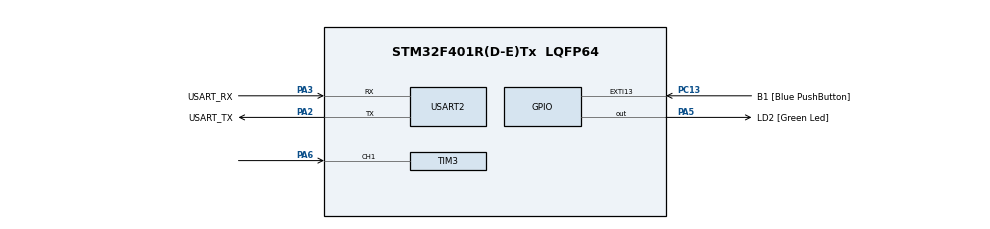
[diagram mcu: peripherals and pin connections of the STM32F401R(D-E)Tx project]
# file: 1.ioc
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Mcu.Family=STM32F4
Mcu.Name=STM32F401R(D-E)Tx
Mcu.Package=LQFP64
NVIC.PriorityGroup=NVIC_PRIORITYGROUP_0
NVIC.TIM3_IRQn=true\:0\:0\:false\:false\:true\:true\:true
PA13.GPIO_Label=TMS
PA13.Mode=Serial_Wire
PA13.Signal=SYS_JTMS-SWDIO
PA14.GPIO_Label=TCK
PA14.Mode=Serial_Wire
PA14.Signal=SYS_JTCK-SWCLK
PA2.GPIO_Label=USART_TX
PA2.GPIO_Mode=GPIO_MODE_AF_PP
PA2.GPIO_PuPd=GPIO_NOPULL
PA2.GPIO_Speed=GPIO_SPEED_FREQ_LOW
PA2.Mode=Asynchronous
PA2.Signal=USART2_TX
PA3.GPIO_Label=USART_RX
PA3.GPIO_Mode=GPIO_MODE_AF_PP
PA3.GPIO_PuPd=GPIO_NOPULL
PA3.GPIO_Speed=GPIO_SPEED_FREQ_LOW
PA3.Mode=Asynchronous
PA3.Signal=USART2_RX
PA5.GPIO_Label=LD2 [Green Led]
PA5.GPIO_Mode=GPIO_MODE_OUTPUT_PP
PA5.GPIO_PuPd=GPIO_NOPULL
PA5.GPIO_Speed=GPIO_SPEED_FREQ_LOW
PA5.Signal=GPIO_Output
PA6.Signal=S_TIM3_CH1
PB3.GPIO_Label=SWO
PB3.Signal=SYS_JTDO-SWO
PC13-ANTI_TAMP.GPIO_Label=B1 [Blue PushButton]
PC13-ANTI_TAMP.GPIO_ModeDefaultEXTI=GPIO_MODE_IT_FALLING
PC13-ANTI_TAMP.GPIO_PuPd=GPIO_NOPULL
PC13-ANTI_TAMP.Signal=GPXTI13
PC14-OSC32_IN.Mode=LSE-External-Oscillator
PC14-OSC32_IN.Signal=RCC_OSC32_IN
PC15-OSC32_OUT.Mode=LSE-External-Oscillator
PC15-OSC32_OUT.Signal=RCC_OSC32_OUT
PH0\ -\ OSC_IN.Mode=HSE-External-Clock-Source
PH0\ -\ OSC_IN.Signal=RCC_OSC_IN
PH1\ -\ OSC_OUT.Mode=HSE-External-Clock-Source
PH1\ -\ OSC_OUT.Signal=RCC_OSC_OUT
ProjectManager.HeapSize=0x200
ProjectManager.StackSize=0x400
ProjectManager.TargetToolchain=SW4STM32
RCC.48MHZClocksFreq_Value=48000000
RCC.AHBFreq_Value=84000000
RCC.APB1CLKDivider=RCC_HCLK_DIV2
RCC.APB1Freq_Value=42000000
RCC.APB1TimFreq_Value=84000000
RCC.APB2Freq_Value=84000000
RCC.APB2TimFreq_Value=84000000
RCC.CortexFreq_Value=84000000
RCC.HCLKFreq_Value=84000000
RCC.HSE_VALUE=8000000
RCC.HSI_VALUE=16000000
RCC.PLLN=336
RCC.PLLP=RCC_PLLP_DIV4
RCC.PLLQ=7
RCC.SYSCLKFreq_VALUE=84000000
RCC.SYSCLKSource=RCC_SYSCLKSOURCE_PLLCLK
RCC.VCOOutputFreq_Value=336000000
SH.S_TIM3_CH1.0=TIM3_CH1,Input_Capture1_from_TI1
TIM3.Channel-Input_Capture1_from_TI1=TIM_CHANNEL_1
TIM3.ICPolarity_CH1=TIM_INPUTCHANNELPOLARITY_BOTHEDGE
TIM3.Period=0xFFFF
TIM3.Prescaler=1999
USART2.VirtualMode=VM_ASYNC
VP_TIM3_VS_ClockSourceINT.Mode=Internal
board=NUCLEO-F401RE

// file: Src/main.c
/* USER CODE BEGIN Header */
/**
  ******************************************************************************
  * @file      10.1     : main.c
  * @brief          : Main program body
  ******************************************************************************
  * @attention
  *
  * <h2><center>&copy; Copyright (c) 2019 STMicroelectronics.
  * All rights reserved.</center></h2>
  *
  * This software component is licensed by ST under BSD 3-Clause license,
  * the "License"; You may not use this file except in compliance with the
  * License. You may obtain a copy of the License at:
  *                        opensource.org/licenses/BSD-3-Clause
  *
  ******************************************************************************
  */
/* USER CODE END Header */

#include "main.h"

void SystemClock_Config(void);
static void MX_GPIO_Init(void);
static void MX_TIM3_Init(void);
static void MX_USART2_UART_Init(void);

int main(void)
{

  /* MCU Configuration--------------------------------------------------------*/

  /* Reset of all peripherals, Initializes the Flash interface and the Systick. */

  LL_APB2_GRP1_EnableClock(LL_APB2_GRP1_PERIPH_SYSCFG);
  LL_APB1_GRP1_EnableClock(LL_APB1_GRP1_PERIPH_PWR);

  NVIC_SetPriorityGrouping(NVIC_PRIORITYGROUP_0);

  /* System interrupt init*/

  /* Configure the system clock */
  SystemClock_Config();

  /* Initialize all configured peripherals */
  MX_GPIO_Init();
  MX_TIM3_Init();
  MX_USART2_UART_Init();
  /* USER CODE BEGIN 2 */
  	LL_TIM_WriteReg(TIM3, CR1, LL_TIM_ReadReg(TIM3,CR1) | 0x01); //enable counter 3
  	LL_TIM_WriteReg(TIM3, DIER, LL_TIM_ReadReg(TIM3,DIER)|0x2); //Enable interrupt channel 1 counter 3
  	LL_TIM_WriteReg(TIM3, CCER, LL_TIM_ReadReg(TIM3,CCER)|0x1); //Enable INPUT CAPTURE  for channel 1 counter 3
  /* USER CODE END 2 */

  /* Infinite loop */
  while (1)
  {

  }
}

void SystemClock_Config(void)
{
  LL_FLASH_SetLatency(LL_FLASH_LATENCY_2);

   if(LL_FLASH_GetLatency() != LL_FLASH_LATENCY_2)
  {
  Error_Handler();
  }
  LL_PWR_SetRegulVoltageScaling(LL_PWR_REGU_VOLTAGE_SCALE2);
  LL_RCC_HSI_SetCalibTrimming(16);
  LL_RCC_HSI_Enable();

   /* Wait till HSI is ready */
  while(LL_RCC_HSI_IsReady() != 1)
  {

  }
  LL_RCC_PLL_ConfigDomain_SYS(LL_RCC_PLLSOURCE_HSI, LL_RCC_PLLM_DIV_16, 336, LL_RCC_PLLP_DIV_4);
  LL_RCC_PLL_Enable();

   /* Wait till PLL is ready */
  while(LL_RCC_PLL_IsReady() != 1)
  {

  }
  LL_RCC_SetAHBPrescaler(LL_RCC_SYSCLK_DIV_1);
  LL_RCC_SetAPB1Prescaler(LL_RCC_APB1_DIV_2);
  LL_RCC_SetAPB2Prescaler(LL_RCC_APB2_DIV_1);
  LL_RCC_SetSysClkSource(LL_RCC_SYS_CLKSOURCE_PLL);

   /* Wait till System clock is ready */
  while(LL_RCC_GetSysClkSource() != LL_RCC_SYS_CLKSOURCE_STATUS_PLL)
  {

  }
  LL_Init1msTick(84000000);
  LL_SYSTICK_SetClkSource(LL_SYSTICK_CLKSOURCE_HCLK);
  LL_SetSystemCoreClock(84000000);
  LL_RCC_SetTIMPrescaler(LL_RCC_TIM_PRESCALER_TWICE);
}

static void MX_TIM3_Init(void)
{

  LL_TIM_InitTypeDef TIM_InitStruct = {0};

  LL_GPIO_InitTypeDef GPIO_InitStruct = {0};

  /* Peripheral clock enable */
  LL_APB1_GRP1_EnableClock(LL_APB1_GRP1_PERIPH_TIM3);

  LL_AHB1_GRP1_EnableClock(LL_AHB1_GRP1_PERIPH_GPIOA);
  /**TIM3 GPIO Configuration
  PA6   ------> TIM3_CH1
  */
  GPIO_InitStruct.Pin = LL_GPIO_PIN_6;
  GPIO_InitStruct.Mode = LL_GPIO_MODE_ALTERNATE;
  GPIO_InitStruct.Speed = LL_GPIO_SPEED_FREQ_LOW;
  GPIO_InitStruct.OutputType = LL_GPIO_OUTPUT_PUSHPULL;
  GPIO_InitStruct.Pull = LL_GPIO_PULL_NO;
  GPIO_InitStruct.Alternate = LL_GPIO_AF_2;
  LL_GPIO_Init(GPIOA, &GPIO_InitStruct);

  /* TIM3 interrupt Init */
  NVIC_SetPriority(TIM3_IRQn, NVIC_EncodePriority(NVIC_GetPriorityGrouping(),0, 0));
  NVIC_EnableIRQ(TIM3_IRQn);

  TIM_InitStruct.Prescaler = 1999;
  TIM_InitStruct.CounterMode = LL_TIM_COUNTERMODE_UP;
  TIM_InitStruct.Autoreload = 0xFFFF;
  TIM_InitStruct.ClockDivision = LL_TIM_CLOCKDIVISION_DIV1;
  LL_TIM_Init(TIM3, &TIM_InitStruct);
  LL_TIM_DisableARRPreload(TIM3);
  LL_TIM_SetClockSource(TIM3, LL_TIM_CLOCKSOURCE_INTERNAL);
  LL_TIM_SetTriggerOutput(TIM3, LL_TIM_TRGO_RESET);
  LL_TIM_DisableMasterSlaveMode(TIM3);
  LL_TIM_IC_SetActiveInput(TIM3, LL_TIM_CHANNEL_CH1, LL_TIM_ACTIVEINPUT_DIRECTTI);
  LL_TIM_IC_SetPrescaler(TIM3, LL_TIM_CHANNEL_CH1, LL_TIM_ICPSC_DIV1);
  LL_TIM_IC_SetFilter(TIM3, LL_TIM_CHANNEL_CH1, LL_TIM_IC_FILTER_FDIV1);
  LL_TIM_IC_SetPolarity(TIM3, LL_TIM_CHANNEL_CH1, LL_TIM_IC_POLARITY_BOTHEDGE);

}

static void MX_USART2_UART_Init(void)
{

  LL_USART_InitTypeDef USART_InitStruct = {0};

  LL_GPIO_InitTypeDef GPIO_InitStruct = {0};

  /* Peripheral clock enable */
  LL_APB1_GRP1_EnableClock(LL_APB1_GRP1_PERIPH_USART2);

  LL_AHB1_GRP1_EnableClock(LL_AHB1_GRP1_PERIPH_GPIOA);
  /**USART2 GPIO Configuration
  PA2   ------> USART2_TX
  PA3   ------> USART2_RX
  */
  GPIO_InitStruct.Pin = USART_TX_Pin|USART_RX_Pin;
  GPIO_InitStruct.Mode = LL_GPIO_MODE_ALTERNATE;
  GPIO_InitStruct.Speed = LL_GPIO_SPEED_FREQ_LOW;
  GPIO_InitStruct.OutputType = LL_GPIO_OUTPUT_PUSHPULL;
  GPIO_InitStruct.Pull = LL_GPIO_PULL_NO;
  GPIO_InitStruct.Alternate = LL_GPIO_AF_7;
  LL_GPIO_Init(GPIOA, &GPIO_InitStruct);

  USART_InitStruct.BaudRate = 115200;
  USART_InitStruct.DataWidth = LL_USART_DATAWIDTH_8B;
  USART_InitStruct.StopBits = LL_USART_STOPBITS_1;
  USART_InitStruct.Parity = LL_USART_PARITY_NONE;
  USART_InitStruct.TransferDirection = LL_USART_DIRECTION_TX_RX;
  USART_InitStruct.HardwareFlowControl = LL_USART_HWCONTROL_NONE;
  USART_InitStruct.OverSampling = LL_USART_OVERSAMPLING_16;
  LL_USART_Init(USART2, &USART_InitStruct);
  LL_USART_ConfigAsyncMode(USART2);
  LL_USART_Enable(USART2);

}

static void MX_GPIO_Init(void)
{
  LL_EXTI_InitTypeDef EXTI_InitStruct = {0};
  LL_GPIO_InitTypeDef GPIO_InitStruct = {0};

  /* GPIO Ports Clock Enable */
  LL_AHB1_GRP1_EnableClock(LL_AHB1_GRP1_PERIPH_GPIOC);
  LL_AHB1_GRP1_EnableClock(LL_AHB1_GRP1_PERIPH_GPIOH);
  LL_AHB1_GRP1_EnableClock(LL_AHB1_GRP1_PERIPH_GPIOA);
  LL_AHB1_GRP1_EnableClock(LL_AHB1_GRP1_PERIPH_GPIOB);

  /**/
  LL_GPIO_ResetOutputPin(LD2_GPIO_Port, LD2_Pin);

  /**/
  LL_SYSCFG_SetEXTISource(LL_SYSCFG_EXTI_PORTC, LL_SYSCFG_EXTI_LINE13);

  /**/
  EXTI_InitStruct.Line_0_31 = LL_EXTI_LINE_13;
  EXTI_InitStruct.LineCommand = ENABLE;
  EXTI_InitStruct.Mode = LL_EXTI_MODE_IT;
  EXTI_InitStruct.Trigger = LL_EXTI_TRIGGER_FALLING;
  LL_EXTI_Init(&EXTI_InitStruct);

  /**/
  LL_GPIO_SetPinPull(B1_GPIO_Port, B1_Pin, LL_GPIO_PULL_NO);

  /**/
  LL_GPIO_SetPinMode(B1_GPIO_Port, B1_Pin, LL_GPIO_MODE_INPUT);

  /**/
  GPIO_InitStruct.Pin = LD2_Pin;
  GPIO_InitStruct.Mode = LL_GPIO_MODE_OUTPUT;
  GPIO_InitStruct.Speed = LL_GPIO_SPEED_FREQ_LOW;
  GPIO_InitStruct.OutputType = LL_GPIO_OUTPUT_PUSHPULL;
  GPIO_InitStruct.Pull = LL_GPIO_PULL_NO;
  LL_GPIO_Init(LD2_GPIO_Port, &GPIO_InitStruct);

}

void Error_Handler(void)
{
}

/************************ (C) COPYRIGHT STMicroelectronics *****END OF FILE****/
